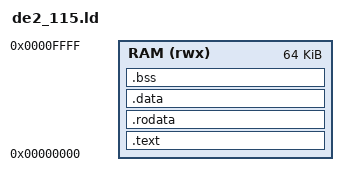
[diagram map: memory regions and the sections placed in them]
/*
 * M2 linker script: a single flat 64 KiB RAM region matching the
 * standalone-core test memory (sim/models/sync_mem.sv, WORDS=16384).
 *
 * This is a deliberate M2-only simplification: there is no ROM/RAM split
 * and no load-address != virtual-address relocation for .data, because
 * everything -- .text, .rodata, .data's initial values, and the as-yet-
 * unwritten .bss space -- lives in the same word-addressable memory that
 * the $readmemh image fills directly at link addresses. crt0.S still
 * explicitly clears .bss at runtime (not relying on the memory happening
 * to be zero) because that is correct practice regardless, and because
 * the hex image generated by scripts/bin_to_readmemh.py from a raw
 * objcopy binary does not emit any bytes for .bss at all (true "memory
 * hole", left at the simulator's default unknown value until written).
 *
 * M3/M4 will replace this with a real ROM (boot/program image in Flash or
 * preloaded SDRAM) + RAM (SDRAM-backed, executable+data) split, at which
 * point a real .data load-address-vs-virtual-address copy becomes
 * necessary in the startup code -- tracked in PROJECT_STATE.md.
 */

MEMORY
{
    RAM (rwx) : ORIGIN = 0x00000000, LENGTH = 64K
}

ENTRY(_start)

SECTIONS
{
    .text : {
        *(.text.start)
        *(.text .text.*)
    } > RAM

    .rodata : {
        *(.rodata .rodata.* .srodata .srodata.*)
    } > RAM

    .data : {
        __data_start = .;
        *(.data .data.* .sdata .sdata.*)
        __data_end = .;
    } > RAM

    .bss : {
        __bss_start = .;
        *(.bss .bss.* .sbss .sbss.*)
        *(COMMON)
        __bss_end = .;
    } > RAM

    . = ALIGN(16);
    __heap_start = .;

    /* Stack grows down from the top of RAM; leave it unassigned to any
       section so its use doesn't collide with .text/.data/.bss growth. */
    _stack_top = ORIGIN(RAM) + LENGTH(RAM);
}
